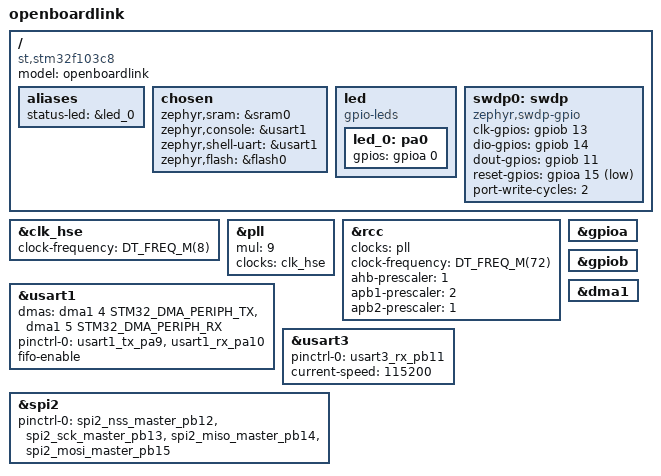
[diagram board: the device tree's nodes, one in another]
/dts-v1/;
#include <st/f1/stm32f103Xb.dtsi>
#include <zephyr/dt-bindings/input/input-event-codes.h>
#include <st/f1/stm32f103c(8-b)tx-pinctrl.dtsi>

/ {
  model = "openboardlink";
  compatible = "st,stm32f103c8";

  aliases {
    status-led = &led_0;
  };

  chosen {
    zephyr,sram = &sram0;
    zephyr,console = &usart1;
    zephyr,shell-uart = &usart1;
    zephyr,flash = &flash0;
  };

  led {
    compatible = "gpio-leds";

    led_0: pa0 {
      gpios = <&gpioa 0 GPIO_ACTIVE_HIGH>;
      status = "okay";
    };
  };

  swdp0: swdp {
    compatible = "zephyr,swdp-gpio";
    clk-gpios = <&gpiob 13 GPIO_ACTIVE_HIGH>;
    dio-gpios = <&gpiob 14 GPIO_ACTIVE_HIGH>;
    dout-gpios = <&gpiob 11 (GPIO_ACTIVE_HIGH | GPIO_PULL_UP)>;
    reset-gpios = <&gpioa 15 (GPIO_ACTIVE_LOW | GPIO_OPEN_DRAIN)>;

    port-write-cycles = <2>;
  };
};

&clk_hse {
  status = "okay";
  clock-frequency = <DT_FREQ_M(8)>;
};

&pll {
  mul = <9>;
  clocks = <&clk_hse>;
  status = "okay";
};

&rcc {
  clocks = <&pll>;
  clock-frequency = <DT_FREQ_M(72)>;
  ahb-prescaler = <1>;
  apb1-prescaler = <2>;
  apb2-prescaler = <1>;
};

&gpioa {
  status = "okay";
};

&gpiob {
  status = "okay";
};

&usart1 {
  dmas = <&dma1 4 STM32_DMA_PERIPH_TX>,  /* DMA1 Channel 4 is USART1_TX */
         <&dma1 5 STM32_DMA_PERIPH_RX>;  /* DMA1 Channel 5 is USART1_RX */
  dma-names = "tx", "rx";
  pinctrl-0 = <&usart1_tx_pa9 &usart1_rx_pa10>;
  pinctrl-names = "default";
  status = "okay";
  fifo-enable;
};

/* SWO capture on USART3 RX (PB11, the default F1 mapping) */
&usart3 {
  pinctrl-0 = <&usart3_rx_pb11>;
  pinctrl-names = "default";
  current-speed = <115200>;   /* set to match the target's SWO rate */
  status = "okay";
};

&dma1 {
  status = "okay";
};

&spi2 {
  status = "okay";
  pinctrl-0 = <&spi2_nss_master_pb12 &spi2_sck_master_pb13
               &spi2_miso_master_pb14 &spi2_mosi_master_pb15>;
  pinctrl-names = "default";
};
